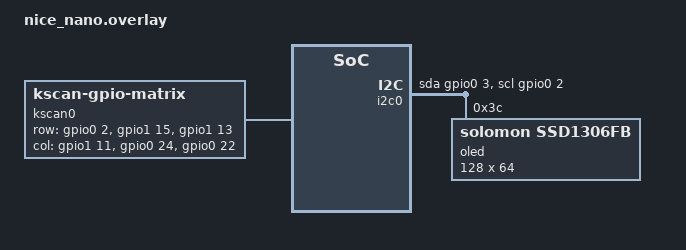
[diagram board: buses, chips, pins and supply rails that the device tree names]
#include <dt-bindings/zmk/matrix.h>

/ {
	chosen {
		zmk,kscan = &kscan0;
		zmk,display = &oled;
	};

	kscan0: kscan {
		compatible = "zmk,kscan-gpio-matrix";
		diode-direction = "col2row";

		row-gpios
			= <&gpio0 2  (GPIO_ACTIVE_HIGH | GPIO_PULL_DOWN)>
			, <&gpio1 15 (GPIO_ACTIVE_HIGH | GPIO_PULL_DOWN)>
			, <&gpio1 13 (GPIO_ACTIVE_HIGH | GPIO_PULL_DOWN)>
			;

		col-gpios
			= <&gpio1 11 GPIO_ACTIVE_HIGH>
			, <&gpio0 24 GPIO_ACTIVE_HIGH>
			, <&gpio0 22 GPIO_ACTIVE_HIGH>
			;
	};
};

&i2c0 {
	status = "okay";
	compatible = "nordic,nrf-twim";
	sda-gpios = <&gpio0 3 (GPIO_ACTIVE_HIGH | GPIO_PULL_UP)>;
	scl-gpios = <&gpio0 2 (GPIO_ACTIVE_HIGH | GPIO_PULL_UP)>;

	oled: ssd1306@3c {
		compatible = "solomon,ssd1306fb";
		reg = <0x3c>;
		width = <128>;
		height = <64>;
		segment-offset = <0>;
		page-offset = <0>;
		display-offset = <0>;
		multiplex-ratio = <63>;
		master-current = <0x0f>;
		invert-colors;
	};
};
